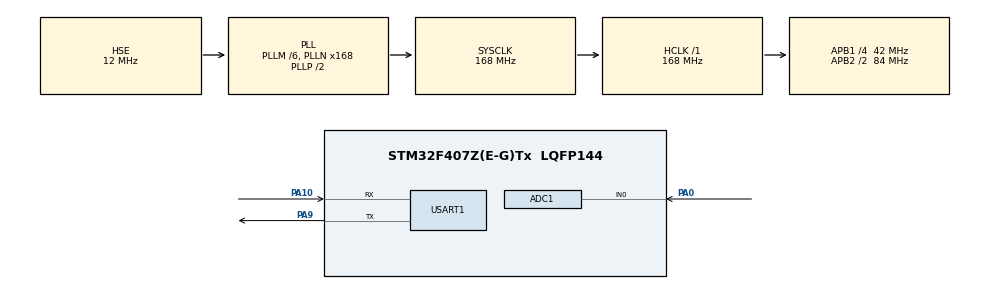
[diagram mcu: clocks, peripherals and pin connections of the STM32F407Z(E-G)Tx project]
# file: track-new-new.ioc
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ADC1.Channel-0\#ChannelRegularConversion=ADC_CHANNEL_0
ADC1.NbrOfConversionFlag=1
ADC1.Rank-0\#ChannelRegularConversion=1
ADC1.SamplingTime-0\#ChannelRegularConversion=ADC_SAMPLETIME_3CYCLES
ADC1.master=1
Mcu.Family=STM32F4
Mcu.Name=STM32F407Z(E-G)Tx
Mcu.Package=LQFP144
NVIC.ADC_IRQn=true\:1\:0\:true\:false\:true\:true\:true
NVIC.PriorityGroup=NVIC_PRIORITYGROUP_4
NVIC.TIM3_IRQn=true\:2\:0\:true\:false\:true\:true\:true
NVIC.TIM4_IRQn=true\:2\:0\:true\:false\:true\:true\:true
NVIC.USART1_IRQn=true\:0\:0\:false\:false\:true\:true\:true
PA0-WKUP.Signal=ADCx_IN0
PA10.Mode=Asynchronous
PA10.Signal=USART1_RX
PA13.Mode=Serial_Wire
PA13.Signal=SYS_JTMS-SWDIO
PA14.Mode=Serial_Wire
PA14.Signal=SYS_JTCK-SWCLK
PA9.Mode=Asynchronous
PA9.Signal=USART1_TX
PH0-OSC_IN.Mode=HSE-External-Oscillator
PH0-OSC_IN.Signal=RCC_OSC_IN
PH1-OSC_OUT.Mode=HSE-External-Oscillator
PH1-OSC_OUT.Signal=RCC_OSC_OUT
ProjectManager.HeapSize=0x200
ProjectManager.StackSize=0x400
ProjectManager.TargetToolchain=MDK-ARM V5.27
RCC.48MHZClocksFreq_Value=84000000
RCC.AHBFreq_Value=168000000
RCC.APB1CLKDivider=RCC_HCLK_DIV4
RCC.APB1Freq_Value=42000000
RCC.APB1TimFreq_Value=84000000
RCC.APB2CLKDivider=RCC_HCLK_DIV2
RCC.APB2Freq_Value=84000000
RCC.APB2TimFreq_Value=168000000
RCC.CortexFreq_Value=168000000
RCC.HCLKFreq_Value=168000000
RCC.HSE_VALUE=12000000
RCC.HSI_VALUE=16000000
RCC.LSE_VALUE=32768
RCC.PLLM=6
RCC.PLLN=168
RCC.PLLSourceVirtual=RCC_PLLSOURCE_HSE
RCC.SYSCLKFreq_VALUE=168000000
RCC.SYSCLKSource=RCC_SYSCLKSOURCE_PLLCLK
RCC.VCOOutputFreq_Value=336000000
SH.ADCx_IN0.0=ADC1_IN0,IN0
TIM3.Period=1000-1
TIM3.Prescaler=84-1
TIM4.Period=1000-1
TIM4.Prescaler=84-1
USART1.VirtualMode=VM_ASYNC
VP_TIM3_VS_ClockSourceINT.Mode=Internal
VP_TIM4_VS_ClockSourceINT.Mode=Internal
board=custom

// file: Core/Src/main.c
/* USER CODE BEGIN Header */
/**
  ******************************************************************************
  * @file           : main.c
  * @brief          : Main program body
  ******************************************************************************
  * @attention
  *
  * <h2><center>&copy; Copyright (c) 2021 STMicroelectronics.
  * All rights reserved.</center></h2>
  *
  * This software component is licensed by ST under BSD 3-Clause license,
  * the "License"; You may not use this file except in compliance with the
  * License. You may obtain a copy of the License at:
  *                        opensource.org/licenses/BSD-3-Clause
  *
  ******************************************************************************
  */
/* USER CODE END Header */
#include "main.h"
#include "adc.h"
#include "tim.h"
#include "usart.h"
#include "gpio.h"
#include "stdio.h"
#include "AD9959.H"

/* USER CODE BEGIN PV */
//u16 ADC_threshold=800;不用阈值判断法这样不太稳定
extern u32 fre;
u16 step_fre=10000;
u32 fre_max=0;
//extern u8 tracking_flag;
extern u8 sweep_finish;
u16 temp=0;
u16 new_val=0;
/* USER CODE END PV */

void SystemClock_Config(void);

int main(void)
{

  /* MCU Configuration--------------------------------------------------------*/

  /* Reset of all peripherals, Initializes the Flash interface and the Systick. */
  HAL_Init();

  /* Configure the system clock */
  SystemClock_Config();

  /* Initialize all configured peripherals */
  MX_GPIO_Init();
  MX_ADC1_Init();
  MX_TIM3_Init();
  MX_TIM4_Init();
  MX_USART1_UART_Init();
  /* USER CODE BEGIN 2 */
	Init_AD9959();
	AD9959_Set_Freq(50700000);
	Write_Amplitude(1,1023);
	//Write_frequence(1,40700000);
	//AD9959_Set_Freq(40700000);
	//HAL_TIM_Base_Start_IT(&htim3);
	HAL_ADC_Start_IT(&hadc1);
	HAL_TIM_Base_Start_IT(&htim4);
  /* USER CODE END 2 */

  /* Infinite loop */
  while (1)
  {

    /* USER CODE BEGIN 3 */
//		if(finish_flag==1)
//		{
//			AD9959_Set_Freq(fre_max);
//			HAL_TIM_Base_Stop_IT(&htim4);
//		}
//		else
//		{
//			AD9959_Set_Freq(fre);
//			HAL_TIM_Base_Start_IT(&htim4);
//		}

//			new_val=Get_Adc(ADC_CHANNEL_5);
//			if(new_val>temp)//比较找最大值。如果新的值大于temp，我就赋给它，只要新值比temp大，就赋给temp,保证temp是最大的值，如果新值小了，就跳过没用，我们只要最大时刻的频率。
//			{
//				temp=new_val;
//				fre_max=fre;
//			}
		if(sweep_finish)//如果扫完，停止扫描，输出此时ADC采样最大的频率，然后开启扫描
		{
			//temp=0;
			HAL_TIM_Base_Stop_IT(&htim4);
			AD9959_Set_Freq(fre_max);
//			HAL_Delay(2000);
//			HAL_TIM_Base_Start_IT(&htim4);
//			sweep_finish=0;

		}
		else
			{

				AD9959_Set_Freq(fre);//如果没有扫完。DDS输出随时间线性变化的频率，只为找到ADC值最大的频点
			}

  }
  /* USER CODE END 3 */
}

void SystemClock_Config(void)
{
  RCC_OscInitTypeDef RCC_OscInitStruct = {0};
  RCC_ClkInitTypeDef RCC_ClkInitStruct = {0};

  /** Configure the main internal regulator output voltage
  */
  __HAL_RCC_PWR_CLK_ENABLE();
  __HAL_PWR_VOLTAGESCALING_CONFIG(PWR_REGULATOR_VOLTAGE_SCALE1);
  /** Initializes the RCC Oscillators according to the specified parameters
  * in the RCC_OscInitTypeDef structure.
  */
  RCC_OscInitStruct.OscillatorType = RCC_OSCILLATORTYPE_HSE;
  RCC_OscInitStruct.HSEState = RCC_HSE_ON;
  RCC_OscInitStruct.PLL.PLLState = RCC_PLL_ON;
  RCC_OscInitStruct.PLL.PLLSource = RCC_PLLSOURCE_HSE;
  RCC_OscInitStruct.PLL.PLLM = 6;
  RCC_OscInitStruct.PLL.PLLN = 168;
  RCC_OscInitStruct.PLL.PLLP = RCC_PLLP_DIV2;
  RCC_OscInitStruct.PLL.PLLQ = 4;
  if (HAL_RCC_OscConfig(&RCC_OscInitStruct) != HAL_OK)
  {
    Error_Handler();
  }
  /** Initializes the CPU, AHB and APB buses clocks
  */
  RCC_ClkInitStruct.ClockType = RCC_CLOCKTYPE_HCLK|RCC_CLOCKTYPE_SYSCLK
                              |RCC_CLOCKTYPE_PCLK1|RCC_CLOCKTYPE_PCLK2;
  RCC_ClkInitStruct.SYSCLKSource = RCC_SYSCLKSOURCE_PLLCLK;
  RCC_ClkInitStruct.AHBCLKDivider = RCC_SYSCLK_DIV1;
  RCC_ClkInitStruct.APB1CLKDivider = RCC_HCLK_DIV4;
  RCC_ClkInitStruct.APB2CLKDivider = RCC_HCLK_DIV2;

  if (HAL_RCC_ClockConfig(&RCC_ClkInitStruct, FLASH_LATENCY_5) != HAL_OK)
  {
    Error_Handler();
  }
}

/* USER CODE BEGIN 4 */
void HAL_ADC_ConvCpltCallback(ADC_HandleTypeDef* hadc)
{
	if(hadc==&hadc1)
	{
			new_val=HAL_ADC_GetValue(&hadc1);
			if(new_val>temp)//比较找最大值。如果新的值大于temp，我就赋给它，只要新值比temp大，就赋给temp,保证temp是最大的值，如果新值小了，就跳过没用，我们只要最大时刻的频率。
			{
				temp=new_val;
				fre_max=fre;
			}
			HAL_ADC_Start_IT(&hadc1);
	}
}
/* USER CODE END 4 */

void Error_Handler(void)
{
  __disable_irq();
  while (1)
  {
  }
}

/************************ (C) COPYRIGHT STMicroelectronics *****END OF FILE****/
